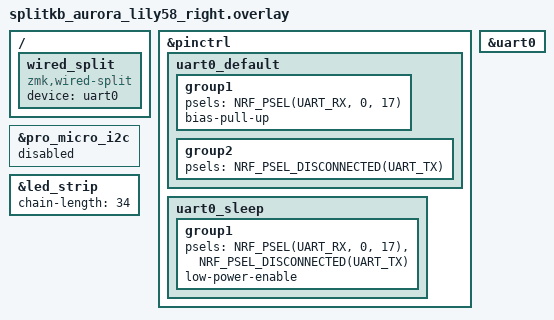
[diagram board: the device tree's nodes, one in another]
/*
 * Wired split over TRRS cable, single data wire, simplex UART.
 * Right = central = RX only on P0.17 (D2).
 * I2C disabled to free up P0.17 for UART.
 */

#include <zephyr/dt-bindings/pinctrl/nrf-pinctrl.h>

&pinctrl {
    uart0_default: uart0_default {
        group1 {
            psels = <NRF_PSEL(UART_RX, 0, 17)>;
            bias-pull-up;
        };
        group2 {
            psels = <NRF_PSEL_DISCONNECTED(UART_TX)>;
        };
    };
    uart0_sleep: uart0_sleep {
        group1 {
            psels = <NRF_PSEL(UART_RX, 0, 17)>,
                    <NRF_PSEL_DISCONNECTED(UART_TX)>;
            low-power-enable;
        };
    };
};

&pro_micro_i2c {
    status = "disabled";
};

&uart0 {
    status = "okay";
};

&led_strip {
    chain-length = <34>; /* 5 underglow + 29 per-key */
};

/ {
    wired_split: wired_split {
        compatible = "zmk,wired-split";
        device = <&uart0>;
    };
};
